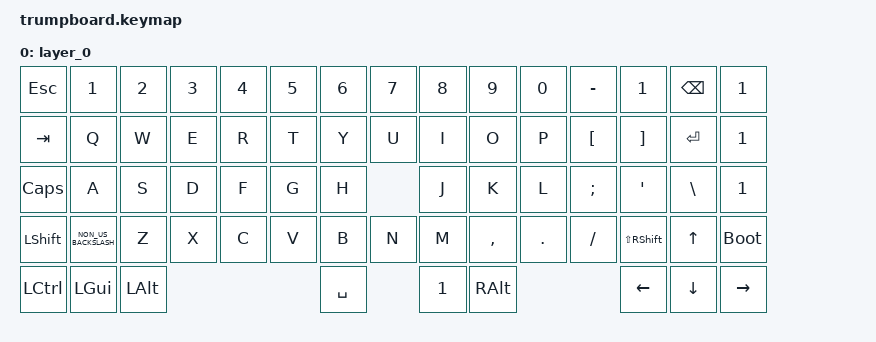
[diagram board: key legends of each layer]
#include <behaviors.dtsi>
#include <dt-bindings/zmk/keys.h>

/ {
    keymap {
        compatible = "zmk,keymap";

        layer_0 {
            bindings = <
&kp ESCAPE      &kp N1                &kp N2        &kp N3  &kp N4        &kp N5  &kp NUMBER_6  &kp N7  &kp N8      &kp N9         &kp N0         &kp MINUS            &kp N1          &kp BACKSPACE   &kp N1
&kp TAB         &kp Q                 &kp W         &kp E   &kp R         &kp T   &kp Y         &kp U   &kp I       &kp O          &kp P          &kp LEFT_BRACKET     &kp RIGHT_BRACKET  &kp ENTER       &kp N1
&kp CAPS        &kp A                 &kp S         &kp D   &kp F         &kp G   &kp H         &kp J   &kp K       &kp L          &kp SEMICOLON  &kp APOSTROPHE       &kp BACKSLASH                      &kp N1
&kp LEFT_SHIFT  &kp NON_US_BACKSLASH  &kp Z         &kp X   &kp C         &kp V   &kp B         &kp N   &kp M       &kp COMMA      &kp DOT        &kp SLASH            &kp LS(RIGHT_SHIFT)&kp UP_ARROW    &bootloader
&kp LCTRL       &kp LEFT_GUI          &kp LEFT_ALT                                &kp SPACE             &kp N1      &kp RIGHT_ALT                                      &kp LEFT_ARROW     &kp DOWN_ARROW  &kp RIGHT_ARROW
            >;
        };
    };
};


